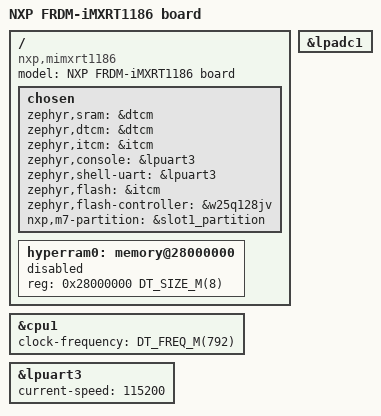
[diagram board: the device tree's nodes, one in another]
/*
 * Copyright 2026 NXP
 *
 * SPDX-License-Identifier: Apache-2.0
 */

/dts-v1/;

#include <nxp/imxrt/nxp_rt118x_cm7.dtsi>
#include <nxp/imxrt/nxp_rt1186.dtsi>
#include "frdm_imxrt1186.dtsi"
#include <freq.h>

/ {
	model = "NXP FRDM-iMXRT1186 board";
	compatible = "nxp,mimxrt1186";

	chosen {
		zephyr,sram = &dtcm;
		zephyr,dtcm = &dtcm;
		zephyr,itcm = &itcm;
		zephyr,console = &lpuart3;
		zephyr,shell-uart = &lpuart3;
		zephyr,flash = &itcm;
		zephyr,flash-controller = &w25q128jv;
		nxp,m7-partition = &slot1_partition;
	};

	hyperram0: memory@28000000 {
		/* Winbond W957A8MFYA5K */
		device_type = "memory";
		reg = <0x28000000 DT_SIZE_M(8)>;
		/*
		 * HyperRAM on FRDM-IMXRT1186 is connected to FlexSPI and initialized by ROM
		 * reading the XMCD configuration from xip/frdmimxrt1186_flexspi_nor_config.c
		 * CM7 sees HyperRAM at a different address (0x28000000) than CM33 (0x38000000)
		 */
		status = "disabled";
	};
};

&cpu1 {
	clock-frequency = <DT_FREQ_M(792)>;
};

&lpuart3 {
	status = "okay";
	current-speed = <115200>;
};

&lpadc1 {
	status = "okay";
};
